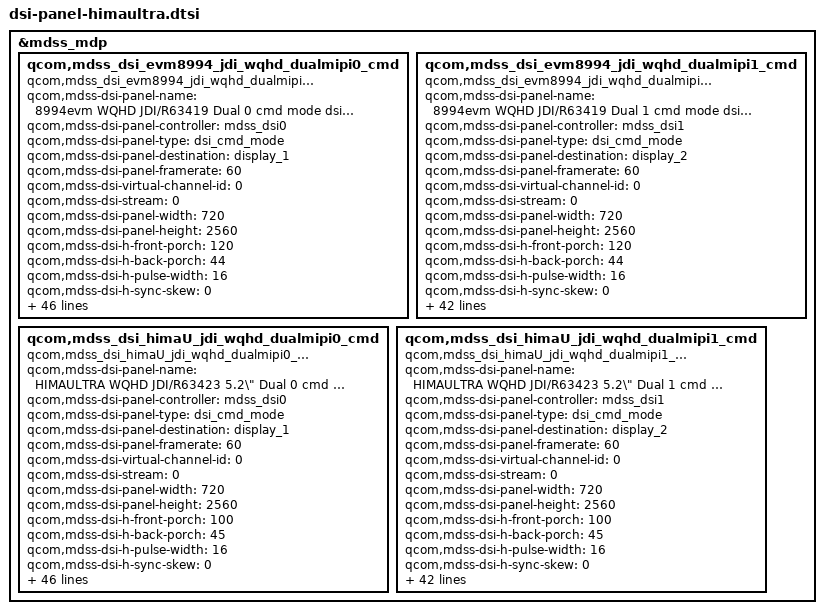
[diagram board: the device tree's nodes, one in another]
&mdss_mdp {
	qcom,mdss_dsi_evm8994_jdi_wqhd_dualmipi0_cmd {
		compatible = "qcom,mdss_dsi_evm8994_jdi_wqhd_dualmipi0_cmd";
		qcom,mdss-dsi-panel-name = "8994evm WQHD JDI/R63419 Dual 0 cmd mode dsi panel";
		qcom,mdss-dsi-panel-controller = <&mdss_dsi0>;
		qcom,mdss-dsi-panel-type = "dsi_cmd_mode";
		qcom,mdss-dsi-panel-destination = "display_1";
		qcom,mdss-dsi-panel-framerate = <60>;
		qcom,mdss-dsi-virtual-channel-id = <0>;
		qcom,mdss-dsi-stream = <0>;
		qcom,mdss-dsi-panel-width = <720>;
		qcom,mdss-dsi-panel-height = <2560>;
		qcom,mdss-dsi-h-front-porch = <120>;
		qcom,mdss-dsi-h-back-porch = <44>;
		qcom,mdss-dsi-h-pulse-width = <16>;
		qcom,mdss-dsi-h-sync-skew = <0>;
		qcom,mdss-dsi-v-back-porch = <4>;
		qcom,mdss-dsi-v-front-porch = <8>;
		qcom,mdss-dsi-v-pulse-width = <4>;
		qcom,mdss-dsi-h-left-border = <0>;
		qcom,mdss-dsi-h-right-border = <0>;
		qcom,mdss-dsi-v-top-border = <0>;
		qcom,mdss-dsi-v-bottom-border = <0>;
		qcom,mdss-dsi-bpp = <24>;
		qcom,mdss-dsi-color-order = "rgb_swap_rgb";
		qcom,mdss-dsi-underflow-color = <0xff>;
		qcom,mdss-dsi-border-color = <0>;
		qcom,mdss-dsi-h-sync-pulse = <0>;
		qcom,mdss-dsi-traffic-mode = "non_burst_sync_event";
		qcom,mdss-dsi-lane-map = "lane_map_0123";
		qcom,mdss-dsi-bllp-eof-power-mode;
		qcom,mdss-dsi-bllp-power-mode;
		qcom,mdss-dsi-panel-broadcast-mode;
		qcom,mdss-dsi-lane-0-state;
		qcom,mdss-dsi-lane-1-state;
		qcom,mdss-dsi-lane-2-state;
		qcom,mdss-dsi-lane-3-state;
		qcom,mdss-dsi-panel-timings = [c7 33 36 00 59 4f 38 38 2b 03
									04 00];
		qcom,mdss-dsi-reset-sequence = <1 11>, <0 2>, <1 11>;
		qcom,mdss-dsi-t-clk-post = <0x04>;
		qcom,mdss-dsi-t-clk-pre = <0x29>;
		qcom,mdss-dsi-bl-pmic-control-type = "bl_ctrl_wled";
		qcom,mdss-dsi-bl-min-level = <1>;
		qcom,mdss-dsi-bl-max-level = <4095>;
		qcom,mdss-dsi-dma-trigger = "trigger_sw";
		qcom,mdss-dsi-mdp-trigger = "none";
		qcom,mdss-dsi-te-pin-select = <1>;
		qcom,mdss-dsi-wr-mem-start = <0x2c>;
		qcom,mdss-dsi-wr-mem-continue = <0x3c>;
		qcom,mdss-dsi-te-dcs-command = <1>;
		qcom,mdss-dsi-te-check-enable;
		qcom,mdss-dsi-te-using-te-pin;
		qcom,mdss-dsi-on-command = [
		/*** exit_sleep_mode ***/
			39 01 00 00 00 00 05 2a 00 00 05 9f
			/* set_column_address */
			39 01 00 00 00 00 05 2b 00 00 09 ff
			/* set_page_address */
			05 01 00 00 78 00 01 11
			/* exit_sleep_mode wait 120 ms*/
			39 01 00 00 00 00 03 44 00 00
			/* set_tear_scanline */
			15 01 00 00 00 00 02 35 00
			/* set_tear_on */
		/*** set_display_on ***/
			15 01 00 00 00 00 02 36 00
			/* set_address_mode */
			15 01 00 00 00 00 02 3a 77
			/* set_pixel_format */
			/* 39 01 00 00 00 00 01 2c */
			/* write_memory_start */
			05 01 00 00 14 00 01 29
			/* set_display_on wait 20 ms */
		/*** Display Brightness and CABC ***/
			15 01 00 00 00 00 02 51 FF
			/* Display Brightness */
			15 01 00 00 00 00 02 53 2C
			/* Control Display */
			15 01 00 00 00 00 02 55 00
			/* Content Adaptive Brightness Control(CABC) */
		];
		qcom,mdss-dsi-on-command-state = "dsi_lp_mode";
		qcom,mdss-dsi-off-command = [05 01 00 00 14 00 01 28
			/* set_display_off */
			15 01 00 00 00 00 02 34 00
			/* set_tear_off */
			05 01 00 00 3c 00 01 10
			/* enter_sleep_mode */
			];
		qcom,mdss-dsi-off-command-state = "dsi_hs_mode";
		qcom,cont-splash-enabled;
	};

	qcom,mdss_dsi_evm8994_jdi_wqhd_dualmipi1_cmd {
		compatible = "qcom,mdss_dsi_evm8994_jdi_wqhd_dualmipi1_cmd";
		qcom,mdss-dsi-panel-name = "8994evm WQHD JDI/R63419 Dual 1 cmd mode dsi panel";
		qcom,mdss-dsi-panel-controller = <&mdss_dsi1>;
		qcom,mdss-dsi-panel-type = "dsi_cmd_mode";
		qcom,mdss-dsi-panel-destination = "display_2";
		qcom,mdss-dsi-panel-framerate = <60>;
		qcom,mdss-dsi-virtual-channel-id = <0>;
		qcom,mdss-dsi-stream = <0>;
		qcom,mdss-dsi-panel-width = <720>;
		qcom,mdss-dsi-panel-height = <2560>;
		qcom,mdss-dsi-h-front-porch = <120>;
		qcom,mdss-dsi-h-back-porch = <44>;
		qcom,mdss-dsi-h-pulse-width = <16>;
		qcom,mdss-dsi-h-sync-skew = <0>;
		qcom,mdss-dsi-v-back-porch = <4>;
		qcom,mdss-dsi-v-front-porch = <8>;
		qcom,mdss-dsi-v-pulse-width = <4>;
		qcom,mdss-dsi-h-left-border = <0>;
		qcom,mdss-dsi-h-right-border = <0>;
		qcom,mdss-dsi-v-top-border = <0>;
		qcom,mdss-dsi-v-bottom-border = <0>;
		qcom,mdss-dsi-bpp = <24>;
		qcom,mdss-dsi-color-order = "rgb_swap_rgb";
		qcom,mdss-dsi-underflow-color = <0xff>;
		qcom,mdss-dsi-border-color = <0>;
		qcom,mdss-dsi-h-sync-pulse = <0>;
		qcom,mdss-dsi-traffic-mode = "non_burst_sync_event";
		qcom,mdss-dsi-lane-map = "lane_map_0123";
		qcom,mdss-dsi-bllp-eof-power-mode;
		qcom,mdss-dsi-bllp-power-mode;
		qcom,mdss-dsi-panel-broadcast-mode;
		qcom,mdss-dsi-lane-0-state;
		qcom,mdss-dsi-lane-1-state;
		qcom,mdss-dsi-lane-2-state;
		qcom,mdss-dsi-lane-3-state;
		qcom,mdss-dsi-panel-timings = [c7 33 36 00 59 4f 38 38 2b 03
									04 00];
		qcom,mdss-dsi-reset-sequence = <1 11>, <0 2>, <1 11>;
		qcom,mdss-dsi-t-clk-post = <0x04>;
		qcom,mdss-dsi-t-clk-pre = <0x29>;
		qcom,mdss-dsi-dma-trigger = "trigger_sw";
		qcom,mdss-dsi-mdp-trigger = "none";
		qcom,mdss-dsi-te-pin-select = <1>;
		qcom,mdss-dsi-wr-mem-start = <0x2c>;
		qcom,mdss-dsi-wr-mem-continue = <0x3c>;
		qcom,mdss-dsi-te-dcs-command = <1>;
		qcom,mdss-dsi-te-check-enable;
		qcom,mdss-dsi-te-using-te-pin;
		qcom,mdss-dsi-on-command = [
		/*** exit_sleep_mode ***/
			39 01 00 00 00 00 05 2a 00 00 05 9f
			/* set_column_address */
			39 01 00 00 00 00 05 2b 00 00 09 ff
			/* set_page_address */
			05 01 00 00 78 00 01 11
			/* exit_sleep_mode wait 120 ms*/
			39 01 00 00 00 00 03 44 00 00
			/* set_tear_scanline */
			15 01 00 00 00 00 02 35 00
			/* set_tear_on */
		/*** set_display_on ***/
			15 01 00 00 00 00 02 36 00
			/* set_address_mode */
			15 01 00 00 00 00 02 3a 77
			/* set_pixel_format */
			/* 39 01 00 00 00 00 01 2c */
			/* write_memory_start */
			05 01 00 00 14 00 01 29
			/* set_display_on wait 20 ms */
		/*** Display Brightness and CABC ***/
			15 01 00 00 00 00 02 51 FF
			/* Display Brightness */
			15 01 00 00 00 00 02 53 2C
			/* Control Display */
			15 01 00 00 00 00 02 55 00
			/* Content Adaptive Brightness Control(CABC) */
		];
		qcom,mdss-dsi-on-command-state = "dsi_lp_mode";
		qcom,mdss-dsi-off-command = [05 01 00 00 14 00 01 28
			/* set_display_off */
			15 01 00 00 00 00 02 34 00
			/* set_tear_off */
			05 01 00 00 3c 00 01 10
			/* enter_sleep_mode */
			];
		qcom,mdss-dsi-off-command-state = "dsi_hs_mode";
		qcom,cont-splash-enabled;
	};

	qcom,mdss_dsi_himaU_jdi_wqhd_dualmipi0_cmd {
		compatible = "qcom,mdss_dsi_himaU_jdi_wqhd_dualmipi0_cmd";
		qcom,mdss-dsi-panel-name = "HIMAULTRA WQHD JDI/R63423 5.2\" Dual 0 cmd mode dsi panel";
		qcom,mdss-dsi-panel-controller = <&mdss_dsi0>;
		qcom,mdss-dsi-panel-type = "dsi_cmd_mode";
		qcom,mdss-dsi-panel-destination = "display_1";
		qcom,mdss-dsi-panel-framerate = <60>;
		qcom,mdss-dsi-virtual-channel-id = <0>;
		qcom,mdss-dsi-stream = <0>;
		qcom,mdss-dsi-panel-width = <720>;
		qcom,mdss-dsi-panel-height = <2560>;
		qcom,mdss-dsi-h-front-porch = <100>;
		qcom,mdss-dsi-h-back-porch = <45>;
		qcom,mdss-dsi-h-pulse-width = <16>;
		qcom,mdss-dsi-h-sync-skew = <0>;
		qcom,mdss-dsi-v-back-porch = <4>;
		qcom,mdss-dsi-v-front-porch = <4>;
		qcom,mdss-dsi-v-pulse-width = <4>;
		qcom,mdss-dsi-h-left-border = <0>;
		qcom,mdss-dsi-h-right-border = <0>;
		qcom,mdss-dsi-v-top-border = <0>;
		qcom,mdss-dsi-v-bottom-border = <0>;
		qcom,mdss-dsi-bpp = <24>;
		qcom,mdss-dsi-color-order = "rgb_swap_rgb";
		qcom,mdss-dsi-underflow-color = <0xff>;
		qcom,mdss-dsi-border-color = <0>;
		qcom,mdss-dsi-h-sync-pulse = <0>;
		qcom,mdss-dsi-traffic-mode = "non_burst_sync_event";
		qcom,mdss-dsi-lane-map = "lane_map_0123";
		qcom,mdss-dsi-bllp-eof-power-mode;
		qcom,mdss-dsi-bllp-power-mode;
		qcom,mdss-dsi-panel-broadcast-mode;
		qcom,mdss-dsi-lane-0-state;
		qcom,mdss-dsi-lane-1-state;
		qcom,mdss-dsi-lane-2-state;
		qcom,mdss-dsi-lane-3-state;
		qcom,mdss-dsi-panel-timings = [2e 32 22 00 62 66 26 36 28 03 04 00];
		qcom,mdss-dsi-reset-sequence = <1 11>, <0 2>, <1 11>;
		qcom,mdss-dsi-t-clk-post = <0x03>;
		qcom,mdss-dsi-t-clk-pre = <0x21>;
		qcom,mdss-dsi-bl-pmic-control-type = "bl_ctrl_wled";
		qcom,mdss-dsi-bl-min-level = <1>;
		qcom,mdss-dsi-bl-max-level = <4095>;
		qcom,mdss-dsi-dma-trigger = "trigger_sw";
		qcom,mdss-dsi-mdp-trigger = "none";
		qcom,mdss-dsi-te-pin-select = <1>;
		qcom,mdss-dsi-wr-mem-start = <0x2c>;
		qcom,mdss-dsi-wr-mem-continue = <0x3c>;
		qcom,mdss-dsi-te-dcs-command = <1>;
		qcom,mdss-dsi-te-check-enable;
		qcom,mdss-dsi-te-using-te-pin;
		qcom,mdss-dsi-on-command = [
		/*** exit_sleep_mode ***/
			39 01 00 00 00 00 05 2a 00 00 05 9f
			/* set_column_address */
			39 01 00 00 00 00 05 2b 00 00 09 ff
			/* set_page_address */
			05 01 00 00 78 00 01 11
			/* exit_sleep_mode wait 120 ms*/
			39 01 00 00 00 00 03 44 00 00
			/* set_tear_scanline */
			15 01 00 00 00 00 02 35 00
			/* set_tear_on */
		/*** set_display_on ***/
			15 01 00 00 00 00 02 36 00
			/* set_address_mode */
			15 01 00 00 00 00 02 3a 77
			/* set_pixel_format */
			/* 39 01 00 00 00 00 01 2c */
			/* write_memory_start */
			05 01 00 00 14 00 01 29
			/* set_display_on wait 20 ms */
		/*** Display Brightness and CABC ***/
			15 01 00 00 00 00 02 51 FF
			/* Display Brightness */
			15 01 00 00 00 00 02 53 2C
			/* Control Display */
			15 01 00 00 00 00 02 55 00
			/* Content Adaptive Brightness Control(CABC) */
		];
		qcom,mdss-dsi-on-command-state = "dsi_lp_mode";
		qcom,mdss-dsi-off-command = [05 01 00 00 14 00 01 28
			/* set_display_off */
			15 01 00 00 00 00 02 34 00
			/* set_tear_off */
			05 01 00 00 3c 00 01 10
			/* enter_sleep_mode */
			];
		qcom,mdss-dsi-off-command-state = "dsi_hs_mode";
		qcom,cont-splash-enabled;
	};

	qcom,mdss_dsi_himaU_jdi_wqhd_dualmipi1_cmd {
		compatible = "qcom,mdss_dsi_himaU_jdi_wqhd_dualmipi1_cmd";
		qcom,mdss-dsi-panel-name = "HIMAULTRA WQHD JDI/R63423 5.2\" Dual 1 cmd mode dsi panel";
		qcom,mdss-dsi-panel-controller = <&mdss_dsi1>;
		qcom,mdss-dsi-panel-type = "dsi_cmd_mode";
		qcom,mdss-dsi-panel-destination = "display_2";
		qcom,mdss-dsi-panel-framerate = <60>;
		qcom,mdss-dsi-virtual-channel-id = <0>;
		qcom,mdss-dsi-stream = <0>;
		qcom,mdss-dsi-panel-width = <720>;
		qcom,mdss-dsi-panel-height = <2560>;
		qcom,mdss-dsi-h-front-porch = <100>;
		qcom,mdss-dsi-h-back-porch = <45>;
		qcom,mdss-dsi-h-pulse-width = <16>;
		qcom,mdss-dsi-h-sync-skew = <0>;
		qcom,mdss-dsi-v-back-porch = <4>;
		qcom,mdss-dsi-v-front-porch = <4>;
		qcom,mdss-dsi-v-pulse-width = <4>;
		qcom,mdss-dsi-h-left-border = <0>;
		qcom,mdss-dsi-h-right-border = <0>;
		qcom,mdss-dsi-v-top-border = <0>;
		qcom,mdss-dsi-v-bottom-border = <0>;
		qcom,mdss-dsi-bpp = <24>;
		qcom,mdss-dsi-color-order = "rgb_swap_rgb";
		qcom,mdss-dsi-underflow-color = <0xff>;
		qcom,mdss-dsi-border-color = <0>;
		qcom,mdss-dsi-h-sync-pulse = <0>;
		qcom,mdss-dsi-traffic-mode = "non_burst_sync_event";
		qcom,mdss-dsi-lane-map = "lane_map_0123";
		qcom,mdss-dsi-bllp-eof-power-mode;
		qcom,mdss-dsi-bllp-power-mode;
		qcom,mdss-dsi-panel-broadcast-mode;
		qcom,mdss-dsi-lane-0-state;
		qcom,mdss-dsi-lane-1-state;
		qcom,mdss-dsi-lane-2-state;
		qcom,mdss-dsi-lane-3-state;
		qcom,mdss-dsi-panel-timings = [2e 32 22 00 62 66 26 36 28 03 04 00];
		qcom,mdss-dsi-reset-sequence = <1 11>, <0 2>, <1 11>;
		qcom,mdss-dsi-t-clk-post = <0x03>;
		qcom,mdss-dsi-t-clk-pre = <0x21>;
		qcom,mdss-dsi-dma-trigger = "trigger_sw";
		qcom,mdss-dsi-mdp-trigger = "none";
		qcom,mdss-dsi-te-pin-select = <1>;
		qcom,mdss-dsi-wr-mem-start = <0x2c>;
		qcom,mdss-dsi-wr-mem-continue = <0x3c>;
		qcom,mdss-dsi-te-dcs-command = <1>;
		qcom,mdss-dsi-te-check-enable;
		qcom,mdss-dsi-te-using-te-pin;
		qcom,mdss-dsi-on-command = [
		/*** exit_sleep_mode ***/
			39 01 00 00 00 00 05 2a 00 00 05 9f
			/* set_column_address */
			39 01 00 00 00 00 05 2b 00 00 09 ff
			/* set_page_address */
			05 01 00 00 78 00 01 11
			/* exit_sleep_mode wait 120 ms*/
			39 01 00 00 00 00 03 44 00 00
			/* set_tear_scanline */
			15 01 00 00 00 00 02 35 00
			/* set_tear_on */
		/*** set_display_on ***/
			15 01 00 00 00 00 02 36 00
			/* set_address_mode */
			15 01 00 00 00 00 02 3a 77
			/* set_pixel_format */
			/* 39 01 00 00 00 00 01 2c */
			/* write_memory_start */
			05 01 00 00 14 00 01 29
			/* set_display_on wait 20 ms */
		/*** Display Brightness and CABC ***/
			15 01 00 00 00 00 02 51 FF
			/* Display Brightness */
			15 01 00 00 00 00 02 53 2C
			/* Control Display */
			15 01 00 00 00 00 02 55 00
			/* Content Adaptive Brightness Control(CABC) */
		];
		qcom,mdss-dsi-on-command-state = "dsi_lp_mode";
		qcom,mdss-dsi-off-command = [05 01 00 00 14 00 01 28
			/* set_display_off */
			15 01 00 00 00 00 02 34 00
			/* set_tear_off */
			05 01 00 00 3c 00 01 10
			/* enter_sleep_mode */
			];
		qcom,mdss-dsi-off-command-state = "dsi_hs_mode";
		qcom,cont-splash-enabled;
	};
};
